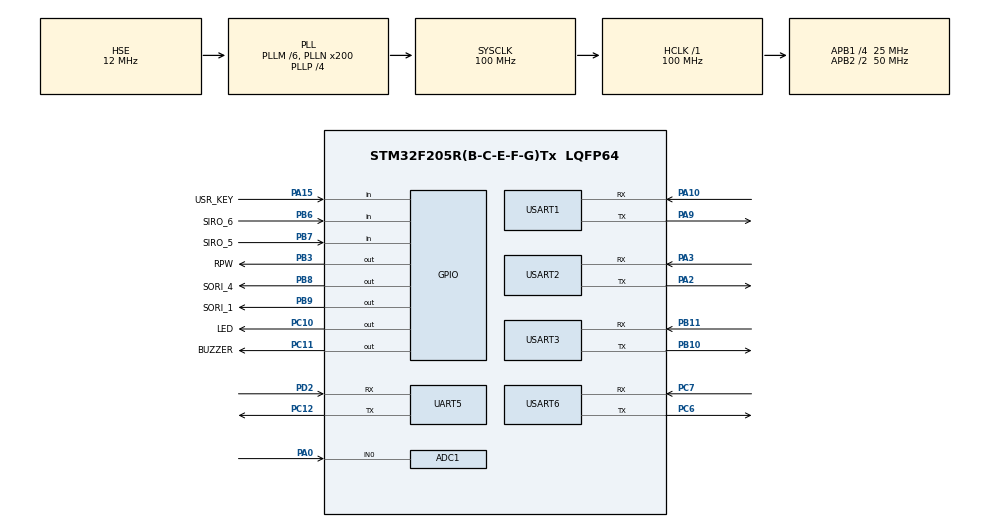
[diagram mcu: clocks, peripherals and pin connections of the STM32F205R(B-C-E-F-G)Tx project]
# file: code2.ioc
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ADC1.Channel-0\#ChannelRegularConversion=ADC_CHANNEL_0
ADC1.ClockPrescaler=ADC_CLOCK_SYNC_PCLK_DIV6
ADC1.ContinuousConvMode=DISABLE
ADC1.NbrOfConversion=1
ADC1.NbrOfConversionFlag=1
ADC1.Rank-0\#ChannelRegularConversion=1
ADC1.SamplingTime-0\#ChannelRegularConversion=ADC_SAMPLETIME_84CYCLES
ADC1.ScanConvMode=DISABLE
ADC1.master=1
Dma.Request0=USART1_RX
Dma.Request1=USART2_TX
Dma.USART1_RX.0.Direction=DMA_PERIPH_TO_MEMORY
Dma.USART1_RX.0.FIFOMode=DMA_FIFOMODE_DISABLE
Dma.USART1_RX.0.Instance=DMA2_Stream2
Dma.USART1_RX.0.MemDataAlignment=DMA_MDATAALIGN_BYTE
Dma.USART1_RX.0.MemInc=DMA_MINC_ENABLE
Dma.USART1_RX.0.Mode=DMA_NORMAL
Dma.USART1_RX.0.PeriphDataAlignment=DMA_PDATAALIGN_BYTE
Dma.USART1_RX.0.PeriphInc=DMA_PINC_DISABLE
Dma.USART1_RX.0.Priority=DMA_PRIORITY_LOW
Dma.USART2_TX.1.Direction=DMA_MEMORY_TO_PERIPH
Dma.USART2_TX.1.FIFOMode=DMA_FIFOMODE_DISABLE
Dma.USART2_TX.1.Instance=DMA1_Stream6
Dma.USART2_TX.1.MemDataAlignment=DMA_MDATAALIGN_BYTE
Dma.USART2_TX.1.MemInc=DMA_MINC_ENABLE
Dma.USART2_TX.1.Mode=DMA_NORMAL
Dma.USART2_TX.1.PeriphDataAlignment=DMA_PDATAALIGN_BYTE
Dma.USART2_TX.1.PeriphInc=DMA_PINC_DISABLE
Dma.USART2_TX.1.Priority=DMA_PRIORITY_LOW
Mcu.Family=STM32F2
Mcu.Name=STM32F205R(B-C-E-F-G)Tx
Mcu.Package=LQFP64
NVIC.ADC_IRQn=true\:0\:0\:false\:false\:true\:true\:true
NVIC.DMA1_Stream6_IRQn=true\:0\:0\:false\:false\:true\:false\:true
NVIC.DMA2_Stream2_IRQn=true\:0\:0\:false\:false\:true\:false\:true
NVIC.PriorityGroup=NVIC_PRIORITYGROUP_4
NVIC.TIM1_UP_TIM10_IRQn=true\:15\:0\:false\:false\:true\:false\:true
NVIC.TimeBase=TIM1_UP_TIM10_IRQn
NVIC.TimeBaseIP=TIM1
NVIC.USART1_IRQn=true\:0\:0\:false\:false\:true\:true\:true
PA0-WKUP.Signal=ADCx_IN0
PA10.Mode=Asynchronous
PA10.Signal=USART1_RX
PA13.Mode=Serial_Wire
PA13.Signal=SYS_JTMS-SWDIO
PA14.Mode=Serial_Wire
PA14.Signal=SYS_JTCK-SWCLK
PA15.GPIO_Label=USR_KEY
PA15.Signal=GPIO_Input
PA2.Mode=Asynchronous
PA2.Signal=USART2_TX
PA3.Mode=Asynchronous
PA3.Signal=USART2_RX
PA9.Mode=Asynchronous
PA9.Signal=USART1_TX
PB10.Mode=Asynchronous
PB10.Signal=USART3_TX
PB11.Mode=Asynchronous
PB11.Signal=USART3_RX
PB3.GPIO_Label=RPW
PB3.Signal=GPIO_Output
PB6.GPIO_Label=SIRO_6
PB6.Signal=GPIO_Input
PB7.GPIO_Label=SIRO_5
PB7.Signal=GPIO_Input
PB8.GPIO_Label=SORI_4
PB8.Signal=GPIO_Output
PB9.GPIO_Label=SORI_1
PB9.Signal=GPIO_Output
PC10.GPIO_Label=LED
PC10.PinState=GPIO_PIN_SET
PC10.Signal=GPIO_Output
PC11.GPIO_Label=BUZZER
PC11.Signal=GPIO_Output
PC12.Mode=Asynchronous
PC12.Signal=UART5_TX
PC6.Mode=Asynchronous
PC6.Signal=USART6_TX
PC7.Mode=Asynchronous
PC7.Signal=USART6_RX
PD2.Mode=Asynchronous
PD2.Signal=UART5_RX
PH0-OSC_IN.Mode=HSE-External-Oscillator
PH0-OSC_IN.Signal=RCC_OSC_IN
PH1-OSC_OUT.Mode=HSE-External-Oscillator
PH1-OSC_OUT.Signal=RCC_OSC_OUT
ProjectManager.HeapSize=0x200
ProjectManager.StackSize=0x400
ProjectManager.TargetToolchain=MDK-ARM V5.32
RCC.48MHZClocksFreq_Value=100000000
RCC.AHBFreq_Value=100000000
RCC.APB1CLKDivider=RCC_HCLK_DIV4
RCC.APB1Freq_Value=25000000
RCC.APB1TimFreq_Value=50000000
RCC.APB2CLKDivider=RCC_HCLK_DIV2
RCC.APB2Freq_Value=50000000
RCC.APB2TimFreq_Value=100000000
RCC.CortexFreq_Value=100000000
RCC.HCLKFreq_Value=100000000
RCC.HSE_VALUE=12000000
RCC.HSI_VALUE=16000000
RCC.LSE_VALUE=32768
RCC.PLLM=6
RCC.PLLN=200
RCC.PLLP=RCC_PLLP_DIV4
RCC.PLLSourceVirtual=RCC_PLLSOURCE_HSE
RCC.SYSCLKFreq_VALUE=100000000
RCC.SYSCLKSource=RCC_SYSCLKSOURCE_PLLCLK
RCC.VCOOutputFreq_Value=400000000
SH.ADCx_IN0.0=ADC1_IN0,IN0
UART5.VirtualMode=Asynchronous
USART1.VirtualMode=VM_ASYNC
USART2.VirtualMode=VM_ASYNC
USART3.VirtualMode=VM_ASYNC
USART6.VirtualMode=VM_ASYNC
VP_SYS_VS_tim1.Mode=TIM1
board=custom

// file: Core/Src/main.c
/* USER CODE BEGIN Header */
/**
  ******************************************************************************
  * @file           : main.c
  * @brief          : Main program body
  ******************************************************************************
  * @attention
  *
  * Copyright (c) 2022 STMicroelectronics.
  * All rights reserved.
  *
  * This software is licensed under terms that can be found in the LICENSE file
  * in the root directory of this software component.
  * If no LICENSE file comes with this software, it is provided AS-IS.
  *
  ******************************************************************************
  */
/* USER CODE END Header */
#include "main.h"
#include "adc.h"
#include "dma.h"
#include "usart.h"
#include "gpio.h"

/* USER CODE BEGIN Includes */
#include "loop.h"

/* USER CODE END Includes */

void SystemClock_Config(void);

/* USER CODE BEGIN 0 */
	uint16_t ADC_Value;
	double true_votage;
/* USER CODE END 0 */

int main(void)
{

  /* MCU Configuration--------------------------------------------------------*/

  /* Reset of all peripherals, Initializes the Flash interface and the Systick. */
  HAL_Init();

  /* Configure the system clock */
  SystemClock_Config();

  /* Initialize all configured peripherals */
  MX_GPIO_Init();
  MX_ADC1_Init();
  MX_UART5_Init();
  MX_USART1_UART_Init();
  MX_USART2_UART_Init();
  MX_USART3_UART_Init();
  MX_DMA_Init();
  MX_USART6_UART_Init();
  /* USER CODE BEGIN 2 */
	loop();

  /* USER CODE END 2 */

  /* Infinite loop */
  /* USER CODE BEGIN WHILE */
  while (1)
  {
//		HAL_UART_Receive(&huart1,&buf,1,0xff);
//		if(buf == 0x55)
//			HAL_GPIO_WritePin(LED_GPIO_Port, LED_Pin, GPIO_PIN_RESET);		//LED ON
//		else
//			HAL_GPIO_WritePin(LED_GPIO_Port, LED_Pin, GPIO_PIN_SET);		//LED ON
//		HAL_ADC_Start(&hadc1);
//		HAL_ADC_PollForConversion(&hadc1, 0xffff);
//
//		ADC_Value = HAL_ADC_GetValue(&hadc1);
//		true_votage = ADC_Value * 3.3 * 6 / 4096;
    /* USER CODE END WHILE */

  }
}

void SystemClock_Config(void)
{
  RCC_OscInitTypeDef RCC_OscInitStruct = {0};
  RCC_ClkInitTypeDef RCC_ClkInitStruct = {0};

  /** Initializes the RCC Oscillators according to the specified parameters
  * in the RCC_OscInitTypeDef structure.
  */
  RCC_OscInitStruct.OscillatorType = RCC_OSCILLATORTYPE_HSE;
  RCC_OscInitStruct.HSEState = RCC_HSE_ON;
  RCC_OscInitStruct.PLL.PLLState = RCC_PLL_ON;
  RCC_OscInitStruct.PLL.PLLSource = RCC_PLLSOURCE_HSE;
  RCC_OscInitStruct.PLL.PLLM = 6;
  RCC_OscInitStruct.PLL.PLLN = 200;
  RCC_OscInitStruct.PLL.PLLP = RCC_PLLP_DIV4;
  RCC_OscInitStruct.PLL.PLLQ = 4;
  if (HAL_RCC_OscConfig(&RCC_OscInitStruct) != HAL_OK)
  {
    Error_Handler();
  }
  /** Initializes the CPU, AHB and APB buses clocks
  */
  RCC_ClkInitStruct.ClockType = RCC_CLOCKTYPE_HCLK|RCC_CLOCKTYPE_SYSCLK
                              |RCC_CLOCKTYPE_PCLK1|RCC_CLOCKTYPE_PCLK2;
  RCC_ClkInitStruct.SYSCLKSource = RCC_SYSCLKSOURCE_PLLCLK;
  RCC_ClkInitStruct.AHBCLKDivider = RCC_SYSCLK_DIV1;
  RCC_ClkInitStruct.APB1CLKDivider = RCC_HCLK_DIV4;
  RCC_ClkInitStruct.APB2CLKDivider = RCC_HCLK_DIV2;

  if (HAL_RCC_ClockConfig(&RCC_ClkInitStruct, FLASH_LATENCY_3) != HAL_OK)
  {
    Error_Handler();
  }
}

void HAL_TIM_PeriodElapsedCallback(TIM_HandleTypeDef *htim)
{
  if (htim->Instance == TIM1) {
    HAL_IncTick();
  }
}

void Error_Handler(void)
{
  __disable_irq();
  while (1)
  {
  }
}
